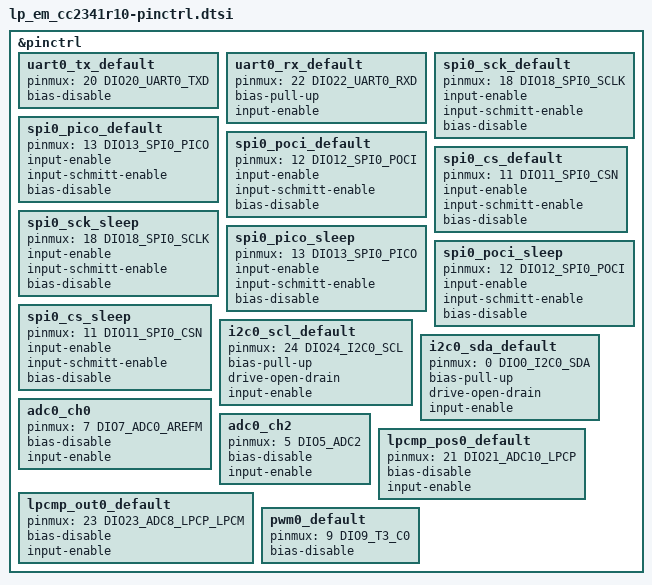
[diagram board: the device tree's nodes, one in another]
/*
 * Copyright (c) 2026 Texas Instruments Incorporated
 *
 * SPDX-License-Identifier: Apache-2.0
 */

#include <zephyr/dt-bindings/pinctrl/cc23x1-pinctrl.h>

&pinctrl {
	/* UART0 */
	uart0_tx_default: uart0_tx_default {
		pinmux = <20 DIO20_UART0_TXD>;
		bias-disable;
	};

	uart0_rx_default: uart0_rx_default {
		pinmux = <22 DIO22_UART0_RXD>;
		bias-pull-up;
		input-enable;
	};

	/* SPI0 */
	spi0_sck_default: spi0_sck_default {
		pinmux = <18 DIO18_SPI0_SCLK>;
		input-enable;
		input-schmitt-enable;
		bias-disable;
	};

	spi0_pico_default: spi0_pico_default {
		pinmux = <13 DIO13_SPI0_PICO>;
		input-enable;
		input-schmitt-enable;
		bias-disable;
	};

	spi0_poci_default: spi0_poci_default {
		pinmux = <12 DIO12_SPI0_POCI>;
		input-enable;
		input-schmitt-enable;
		bias-disable;
	};

	spi0_cs_default: spi0_cs_default {
		pinmux = <11 DIO11_SPI0_CSN>;
		input-enable;
		input-schmitt-enable;
		bias-disable;
	};

	spi0_sck_sleep: spi0_sck_sleep {
		pinmux = <18 DIO18_SPI0_SCLK>;
		input-enable;
		input-schmitt-enable;
		bias-disable;
	};

	spi0_pico_sleep: spi0_pico_sleep {
		pinmux = <13 DIO13_SPI0_PICO>;
		input-enable;
		input-schmitt-enable;
		bias-disable;
	};

	spi0_poci_sleep: spi0_poci_sleep {
		pinmux = <12 DIO12_SPI0_POCI>;
		input-enable;
		input-schmitt-enable;
		bias-disable;
	};

	spi0_cs_sleep: spi0_cs_sleep {
		pinmux = <11 DIO11_SPI0_CSN>;
		input-enable;
		input-schmitt-enable;
		bias-disable;
	};
	
	/* I2C0 */
	i2c0_scl_default: i2c0_scl_default {
		pinmux = <24 DIO24_I2C0_SCL>;
		bias-pull-up;
		drive-open-drain;
		input-enable;
	};

	i2c0_sda_default: i2c0_sda_default {
		pinmux = <0 DIO0_I2C0_SDA>;
		bias-pull-up;
		drive-open-drain;
		input-enable;
	};

	/* ADC0 */
	adc0_ch0: adc0_ch0 {
		pinmux = <7 DIO7_ADC0_AREFM>;
		bias-disable;
		input-enable;
	};

	adc0_ch2: adc0_ch2 {
		pinmux = <5 DIO5_ADC2>;
		bias-disable;
		input-enable;
	};

	/* LPCMP */
	lpcmp_pos0_default: lpcmp_pos0_default {
		pinmux = <21 DIO21_ADC10_LPCP>;
		bias-disable;
		input-enable;
	};

	lpcmp_out0_default: lpcmp_out0_default {
		pinmux = <23 DIO23_ADC8_LPCP_LPCM>;
		bias-disable;
		input-enable;
	};

	/* PWM0 */
	pwm0_default: pwm0_default {
		pinmux = <9 DIO9_T3_C0>;
		bias-disable;
	};
};
